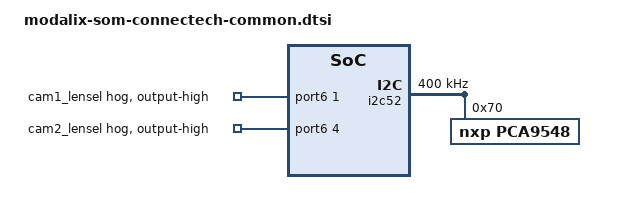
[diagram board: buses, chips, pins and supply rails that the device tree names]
// SPDX-License-Identifier: (GPL-2.0+ OR MIT)
/*
 * Copyright (c) 2026 SiMa ai
 */

/dts-v1/;
/plugin/;

&port6 {
    cam-len0 {
            gpio-hog;
            /* Set port6 gpio1 to GPIO_ACTIVE_HIGH mode */
            gpios = <1 0>;
            output-high;
            line-name = "cam1_lensel";
    };
    cam-len1 {
            gpio-hog;
            /* Set port6 gpio4 to GPIO_ACTIVE_HIGH mode */
            gpios = <4 0>;
            output-high;
            line-name = "cam2_lensel";
    };
};


&i2c52 {
    status = "okay";
    clock-frequency = <400000>;
    #address-cells = <1>;
    #size-cells = <0>;
    pca9548: i2c-mux@70 {
        compatible = "nxp,pca9548";
        reg = <0x70>;
        idle-state = <0>;
        i2c0: i2c@0 {
            reg = <0>;
            #address-cells = <1>;
            #size-cells = <0>;
        };
        i2c1: i2c@1 {
            reg = <1>;
            #address-cells = <1>;
            #size-cells = <0>;
        };
        i2c2: i2c@2 {
            reg = <2>;
            #address-cells = <1>;
            #size-cells = <0>;
        };
        i2c3: i2c@3 {
            reg = <3>;
            #address-cells = <1>;
            #size-cells = <0>;
        };
    };
};
